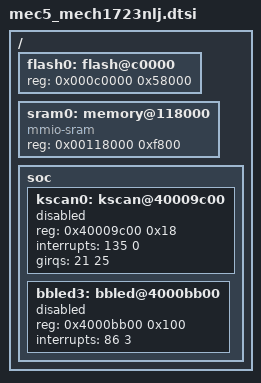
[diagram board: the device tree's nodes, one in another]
/*
 * Copyright (c) 2024 Microchip Technology Inc.
 *
 * SPDX-License-Identifier: Apache-2.0
 */

#include <arm/armv7-m.dtsi>

#include "mec5.dtsi"

/ {
	flash0: flash@c0000 {
		reg = <0x000c0000 0x58000>;
	};

	sram0: memory@118000 {
		compatible = "mmio-sram";
		reg = <0x00118000 0xf800>;
	};

	soc {
		#include "mec5/mec5_dma_chan16.dtsi"
		#include "mec5/mec5_gpspi_v1.dtsi"
		#include "mec5/mec5_eeprom_8kb.dtsi"
		#include "mec5/mec5_pkg176_pwms.dtsi"
		#include "mec5/mec5_rcid.dtsi"
		#include "mec5/mec5_bclink.dtsi"

		kscan0: kscan@40009c00 {
			reg = <0x40009c00 0x18>;
			interrupts = <135 0>;
			girqs = <21 25>;
			status = "disabled";
		};

		bbled3: bbled@4000bb00 {
			reg = <0x4000bb00 0x100>;
			interrupts = <86 3>;
			status = "disabled";
		};
	};
};
